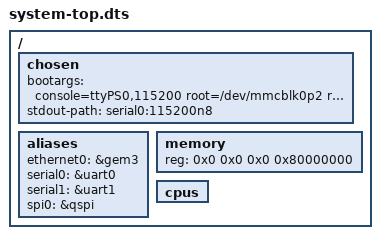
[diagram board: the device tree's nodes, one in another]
/*
 * CAUTION: This file is automatically generated by Xilinx.
 * Version:  
 * Today is: Mon Jul  3 14:17:05 2017
*/


/dts-v1/;
/include/ "zynqmp.dtsi"
/include/ "zynqmp-clk-ccf.dtsi"
/*/include/ "pl.dtsi"*/
/include/ "pcw.dtsi"
/include/ "openamp-overlay.dtsi"
/ {
	chosen {
		bootargs = "console=ttyPS0,115200 root=/dev/mmcblk0p2 rw earlyprintk rootfstype=ext4 rootwait earlycon clk_ignore_unused";
		stdout-path = "serial0:115200n8";
	};
	aliases {
		ethernet0 = &gem3;
		serial0 = &uart0;
		serial1 = &uart1;
		spi0 = &qspi;
	};
	memory {
		device_type = "memory";
		reg = <0x0 0x0 0x0 0x80000000>;
	};
	cpus {
	};
};
